# STM32H7RSxx register map
File version: 0.2
CPU: CM7 r0p1, little endian, MPU, FPU, 4 interrupt priority bits
Registers are 32-bit, read-write, reset 0x0 unless marked. A register's access mark holds for its fields unless they carry their own. Offsets are from the block's base; [hi:lo] are bit positions; {n}, {i} and the like mark numbered series; 'fields as' and 'values as' point back to an identical list.

## TIM9 — General-purpose timers
Base 0x42004C00
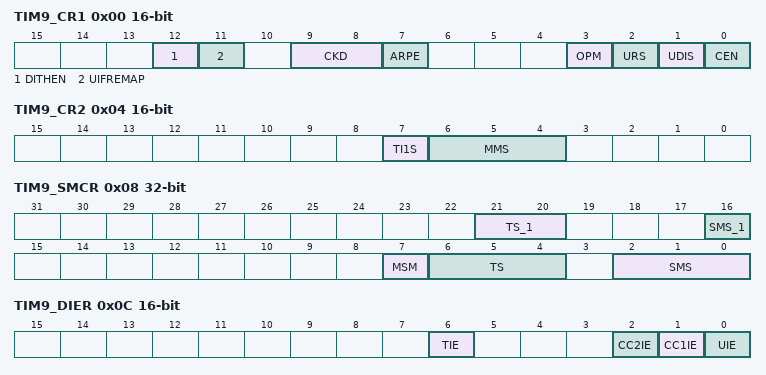
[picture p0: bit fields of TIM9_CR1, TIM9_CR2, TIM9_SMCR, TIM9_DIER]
0x00 TIM9_CR1 16-bit — TIM9 control register 1
  [12] DITHEN — Dithering enable Note: The DITHEN bit can only be modified when CEN bit is reset.
    0=Dithering disabled; 1=Dithering enabled
  [11] UIFREMAP — UIF status bit remapping
    0=No remapping. UIF status bit is not copied to TIMx_CNT register bit 31.; 1=Remapping enabled. UIF status bit is copied to TIMx_CNT register bit 31.
  [9:8] CKD — Clock division This bit-field indicates the division ratio between the timer clock (tim_ker_ck) frequency and sampling clock used by the digital filters (tim_tix),
    0=t<sub>DTS</sub> = t<sub>tim_ker_ck</sub>; 1=t<sub>DTS</sub> = 2 � t<sub>tim_ker_ck</sub>; 2=t<sub>DTS</sub> = 4 � t<sub>tim_ker_ck</sub>
  [7] ARPE — Auto-reload preload enable
    0=TIMx_ARR register is not buffered; 1=TIMx_ARR register is buffered
  [3] OPM — One-pulse mode
    0=Counter is not stopped on the update event; 1=Counter stops counting on the next update event (clearing the CEN bit)
  [2] URS — Update request source This bit is set and cleared by software to select the UEV event sources. Counter overflow Setting the UG bit Update generation through the slave mode controller
    0=Any of the following events generates an update interrupt if enabled. These events can be:; 1=Only counter overflow generates an update interrupt if enabled
  [1] UDIS — Update disable This bit is set and cleared by software to enable/disable update event (UEV) generation. Counter overflow Setting the UG bit Buffered registers are then loaded with their preload values.
    0=UEV enabled. An UEV is generated by one of the following events:; 1=UEV disabled. No UEV is generated, shadow registers keep their value (ARR, PSC, CCRx). The counter and the prescaler are reinitialized if the UG bit is set.
  [0] CEN — Counter enable CEN is cleared automatically in one-pulse mode, when an update event occurs. Note: External clock and gated mode can work only if the CEN bit has been previously set by software. However trigger mode can set the CEN bit automatically by hardware.
    0=Counter disabled; 1=Counter enabled
0x04 TIM9_CR2 16-bit — TIM12 control register 2
  [7] TI1S — tim_ti1 selection
    0=The tim_ti1_in[15:0] multiplexer output is connected to tim_ti1 input; 1=The tim_ti1_in[15:0] and tim_ti2_in[15:0] multiplexers output are connected to the tim_ti1 input (XOR combination)
  [6:4] MMS — Master mode selection These bits allow to select the information to be sent in master mode to slave timers for synchronization (tim_trgo). The combination is as follows:
    0=Reset - the UG bit from the TIMx_EGR register is used as trigger output (tim_trgo). If the reset is generated by the trigger input (slave mode controller configured in reset mode) then the signal on tim_trgo is delayed compared to the actual reset.; 1=Enable - the Counter Enable signal CNT_EN is used as trigger output (tim_trgo). It is useful to start several timers at the same time or to control a window in which a slave timer is enable. The Counter Enable signal is generated by a logic AND between CEN control bit and the trigger input when configured in gated mode. When the Counter Enable signal is controlled by the trigger input, there is a delay on tim_trgo, except if the master/slave mode is selected (see the MSM bit description in TIMx_SMCR register).; 2=Update - The update event is selected as trigger output (tim_trgo). For instance a master timer can then be used as a prescaler for a slave timer.; 3=Compare Pulse - The trigger output send a positive pulse when the CC1IF flag is to be set (even if it was already high), as soon as a capture or a compare match occurred (tim_trgo); 4=Compare - tim_oc1refc signal is used as trigger output (tim_trgo); 5=Compare - tim_oc2refc signal is used as trigger output (tim_trgo)
0x08 TIM9_SMCR — TIM9 slave mode control register
  [21:20] TS_1 — TS[4:3]
  [16] SMS_1 — SMS[3]
  [7] MSM — Master/Slave mode
    0=No action; 1=The effect of an event on the trigger input (tim_trgi) is delayed to allow a perfect synchronization between the current timer and its slaves (through tim_trgo). It is useful in order to synchronize several timers on a single external event.
  [6:4] TS — TS[0]: Trigger selection This TS[4:0] bitfield selects the trigger input to be used to synchronize the counter. Others: Reserved See Table 658: TIMx internal trigger connection for more details on the meaning of tim_itrx for each timer. Note: These bits must be changed only when they are not used (for example when SMS=’000’) to avoid wrong edge detections at the transition.
    {v}=Internal Trigger {v} (tim_itr{v}) (v=0..3); 4=tim_ti1 Edge Detector (tim_ti1f_ed); 5=Filtered Timer Input 1 (tim_ti1fp1); 6=Filtered Timer Input 2 (tim_ti2fp2); {v}=Internal Trigger {v-4} (tim_itr{v-4}) (v=8..14); {v}=Internal Trigger 10 (tim_itr{v-4}) (v=15..19)
  [2:0] SMS — SMS[0]: Slave mode selection When external signals are selected the active edge of the trigger signal (tim_trgi) is linked to the polarity selected on the external input (see Input Control register and Control Register description. Other codes: reserved. Note: The gated mode (including gated + reset mode) must not be used if tim_ti1f_ed is selected as the trigger input (TS=’00100’). Indeed, tim_ti1f_ed outputs 1 pulse for each transition on tim_ti1f, whereas the gated mode checks the level of the trigger signal. Note: The clock of the slave peripherals (timer, ADC,...) receiving the tim_trgo signals must be enabled prior to receive events from the master timer, and must not be changed on-the-fly while triggers are received from the master timer.
    0=Slave mode disabled - if CEN = ‘1’ then the prescaler is clocked directly by the internal clock; 4=Reset Mode - Rising edge of the selected trigger input (tim_trgi) reinitializes the counter and generates an update of the registers; 5=Gated Mode - The counter clock is enabled when the trigger input (tim_trgi) is high. The counter stops (but is not reset) as soon as the trigger becomes low. Both start and stop of the counter are controlled.; 6=Trigger Mode - The counter starts at a rising edge of the trigger tim_trgi (but it is not reset). Only the start of the counter is controlled.; 7=External Clock Mode 1 - Rising edges of the selected trigger (tim_trgi) clock the counter; 8=Combined reset + trigger mode - Rising edge of the selected trigger input (tim_trgi) reinitializes the counter, generates an update of the registers and starts the counter; 9=Combined gated + reset mode - The counter clock is enabled when the trigger input (tim_trgi) is high. The counter stops and is reset) as soon as the trigger becomes low. Both start and stop of the counter are controlled.
0x0C TIM9_DIER 16-bit — TIM9 Interrupt enable register
  [6] TIE — Trigger interrupt enable
    0=Trigger interrupt disabled; 1=Trigger interrupt enabled
  [2] CC2IE — Capture/Compare 2 interrupt enable
    0=CC2 interrupt disabled; 1=CC2 interrupt enabled
  [1] CC1IE — Capture/Compare 1 interrupt enable
    0=CC1 interrupt disabled; 1=CC1 interrupt enabled
  [0] UIE — Update interrupt enable
    0=Update interrupt disabled; 1=Update interrupt enabled
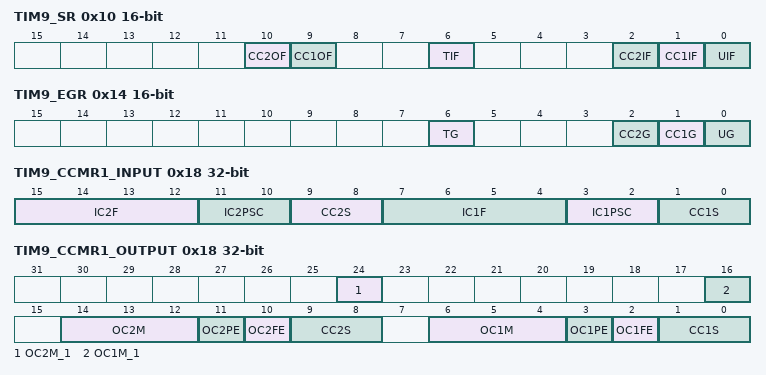
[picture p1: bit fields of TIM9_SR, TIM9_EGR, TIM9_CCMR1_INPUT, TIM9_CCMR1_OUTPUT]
0x10 TIM9_SR 16-bit — TIM9 status register
  [10] CC2OF — Capture/compare 2 overcapture flag refer to CC1OF description
  [9] CC1OF — Capture/Compare 1 overcapture flag This flag is set by hardware only when the corresponding channel is configured in input capture mode. It is cleared by software by writing it to ‘0’.
    0=No overcapture has been detected; 1=The counter value has been captured in TIMx_CCR1 register while CC1IF flag was already set
  [6] TIF — Trigger interrupt flag This flag is set by hardware on the TRG trigger event (active edge detected on tim_trgi input when the slave mode controller is enabled in all modes but gated mode. It is set when the counter starts or stops when gated mode is selected. It is cleared by software.
    0=No trigger event occurred; 1=Trigger interrupt pending
  [2] CC2IF — Capture/Compare 2 interrupt flag refer to CC1IF description
  [1] CC1IF — Capture/compare 1 interrupt flag This flag is set by hardware. It is cleared by software (input capture or output compare mode) or by reading the TIMx_CCR1 register (input capture mode only). If channel CC1 is configured as output: this flag is set when he content of the counter TIMx_CNT matches the content of the TIMx_CCR1 register. When the content of TIMx_CCR1 is greater than the content of TIMx_ARR, the CC1IF bit goes high on the counter overflow (in up-counting and up/down-counting modes) or underflow (in down-counting mode). There are 3 possible options for flag setting in center-aligned mode, refer to the CMS bits in the TIMx_CR1 register for the full description. If channel CC1 is configured as input: this bit is set when counter value has been captured in TIMx_CCR1 register (an edge has been detected on tim_ic1, as per the edge sensitivity defined with the CC1P and CC1NP bits setting, in TIMx_CCER).
    0=No compare match / No input capture occurred; 1=A compare match or an input capture occurred
  [0] UIF — Update interrupt flag This bit is set by hardware on an update event. It is cleared by software. At overflow and if UDIS=’0’ in the TIMx_CR1 register. When CNT is reinitialized by software using the UG bit in TIMx_EGR register, if URS=’0’ and UDIS=’0’ in the TIMx_CR1 register. When CNT is reinitialized by a trigger event (refer toSection 67.7.3: TIMx slave mode control register (TIMx_SMCR)(x = 9, 12) ), if URS=’0’ and UDIS=’0’ in the TIMx_CR1 register.
    0=No update occurred; 1=Update interrupt pending. This bit is set by hardware when the registers are updated:
0x14 TIM9_EGR 16-bit wo — TIM9 event generation register
  [6] TG — Trigger generation This bit is set by software in order to generate an event, it is automatically cleared by hardware.
    0=No action; 1=The TIF flag is set in the TIMx_SR register. Related interrupt can occur if enabled
  [2] CC2G — Capture/compare 2 generation refer to CC1G description
  [1] CC1G — Capture/compare 1 generation This bit is set by software to generate an event, it is automatically cleared by hardware. If channel CC1 is configured as output: the CC1IF flag is set, the corresponding interrupt is sent if enabled. If channel CC1 is configured as input: The current counter value is captured in the TIMx_CCR1 register. The CC1IF flag is set, the corresponding interrupt is sent if enabled. The CC1OF flag is set if the CC1IF flag was already high.
    0=No action; 1=A capture/compare event is generated on channel 1:
  [0] UG — Update generation This bit can be set by software, it is automatically cleared by hardware.
    0=No action; 1=Re-initializes the counter and generates an update of the registers. The prescaler counter is also cleared and the prescaler ratio is not affected. The counter is cleared.
0x18 TIM9_CCMR1_INPUT — TIM9 capture/compare mode register 1
  [15:12] IC2F — Input capture 2 filter
  [11:10] IC2PSC — Input capture 2 prescaler
  [9:8] CC2S — Capture/compare 2 selection This bitfield defines the direction of the channel (input/output) as well as the used input. Note: The CC2S bits are writable only when the channel is OFF (CC2E = 0 in TIMx_CCER).
    0=CC2 channel is configured as output; 1=CC2 channel is configured as input, IC2 is mapped on tim_ti2; 2=CC2 channel is configured as input, IC2 is mapped on tim_ti1; 3=CC2 channel is configured as input, IC2 is mapped on tim_trc. This mode works only if an internal trigger input is selected through the TS bit (TIMx_SMCR register)
  [7:4] IC1F — Input capture 1 filter This bitfield defines the frequency used to sample the tim_ti1 input and the length of the digital filter applied to tim_ti1. The digital filter is made of an event counter in which N consecutive events are needed to validate a transition on the output:
    0=No filter, sampling is done at f<sub>DTS</sub>; 1=f<sub>SAMPLING</sub>=f<sub>tim_ker_ck</sub>, N=2; 2=f<sub>SAMPLING</sub>=f<sub>tim_ker_ck</sub>, N=4; 3=f<sub>SAMPLING</sub>=f<sub>tim_ker_ck</sub>, N=8; 4=f<sub>SAMPLING</sub>=f<sub>DTS</sub>/2, N=6; 5=f<sub>SAMPLING</sub>=f<sub>DTS</sub>/2, N=8; 6=f<sub>SAMPLING</sub>=f<sub>DTS</sub>/4, N=6; 7=f<sub>SAMPLING</sub>=f<sub>DTS</sub>/4, N=8; 8=f<sub>SAMPLING</sub>=f<sub>DTS</sub>/8, N=6; 9=f<sub>SAMPLING</sub>=f<sub>DTS</sub>/8, N=8; 10=f<sub>SAMPLING</sub>=f<sub>DTS</sub>/16, N=5; 11=f<sub>SAMPLING</sub>=f<sub>DTS</sub>/16, N=6; 12=f<sub>SAMPLING</sub>=f<sub>DTS</sub>/16, N=8; 13=f<sub>SAMPLING</sub>=f<sub>DTS</sub>/32, N=5; 14=f<sub>SAMPLING</sub>=f<sub>DTS</sub>/32, N=6; 15=f<sub>SAMPLING</sub>=f<sub>DTS</sub>/32, N=8
  [3:2] IC1PSC — Input capture 1 prescaler This bitfield defines the ratio of the prescaler acting on the CC1 input (tim_ic1). The prescaler is reset as soon as CC1E=’0’ (TIMx_CCER register).
    0=no prescaler, capture is done each time an edge is detected on the capture input; 1=capture is done once every 2 events; 2=capture is done once every 4 events; 3=capture is done once every 8 events
  [1:0] CC1S — Capture/Compare 1 selection This bitfield defines the direction of the channel (input/output) as well as the used input. Note: The CC1S bits are writable only when the channel is OFF (CC1E = 0 in TIMx_CCER).
    0=CC1 channel is configured as output; 1=CC1 channel is configured as input, tim_ic1 is mapped on tim_ti1; 2=CC1 channel is configured as input, tim_ic1 is mapped on tim_ti2; 3=CC1 channel is configured as input, tim_ic1 is mapped on tim_trc. This mode is working only if an internal trigger input is selected through TS bit (TIMx_SMCR register)
0x18 TIM9_CCMR1_OUTPUT (alternate view of TIM9_CCMR1_INPUT) — TIM9 capture/compare mode register 1
  [24] OC2M_1 — OC2M[3]
  [16] OC1M_1 — OC1M[3]
  [14:12] OC2M — OC2M[2:0]: Output compare 2 mode Refer to OC1M[3:0] for bit description.
  [11] OC2PE — Output compare 2 preload enable
  [10] OC2FE — Output compare 2 fast enable
  [9:8] CC2S — Capture/Compare 2 selection This bitfield defines the direction of the channel (input/output) as well as the used input. Note: The CC2S bits are writable only when the channel is OFF (CC2E = 0 in TIMx_CCER).
    0=CC2 channel is configured as output; 1=CC2 channel is configured as input, IC2 is mapped on tim_ti2; 2=CC2 channel is configured as input, IC2 is mapped on tim_ti1; 3=CC2 channel is configured as input, IC2 is mapped on tim_trc. This mode works only if an internal trigger input is selected through the TS bit (TIMx_SMCR register
  [6:4] OC1M — OC1M[2:0]: Output compare 1 mode (refer to bit 16 for OC1M[3]) These bits define the behavior of the output reference signal tim_oc1ref from which tim_oc1 is derived. tim_oc1ref is active high whereas the active level of tim_oc1 depends on the CC1P. Note: In PWM mode 1 or 2, the OCREF level changes only when the result of the comparison changes or when the output compare mode switches from “frozen” mode to “PWM” mode.
    0=Frozen - The comparison between the output compare register TIMx_CCR1 and the counter TIMx_CNT has no effect on the outputs.(this mode is used to generate a timing base); 1=Set channel 1 to active level on match. The tim_oc1ref signal is forced high when the TIMx_CNT counter matches the capture/compare register 1 (TIMx_CCR1).; 2=Set channel 1 to inactive level on match. The tim_oc1ref signal is forced low when the TIMx_CNT counter matches the capture/compare register 1 (TIMx_CCR1).; 3=Toggle - tim_oc1ref toggles when TIMx_CNT=TIMx_CCR1; 4=Force inactive level - tim_oc1ref is forced low; 5=Force active level - tim_oc1ref is forced high; 6=PWM mode 1 - channel 1 is active as long as TIMx_CNT<TIMx_CCR1 else it is inactive; 7=PWM mode 2 - channel 1 is inactive as long as TIMx_CNT<TIMx_CCR1 else it is active; 8=Retrigerrable OPM mode 1 - The channel is active until a trigger event is detected (on tim_trgi signal). Then, a comparison is performed as in PWM mode 1 and the channels becomes active again at the next update.; 9=Retrigerrable OPM mode 2 - The channel is inactive until a trigger event is detected (on tim_trgi signal). Then, a comparison is performed as in PWM mode 2 and the channels becomes inactive again at the next update.; 12=Combined PWM mode 1 - tim_oc1ref has the same behavior as in PWM mode 1. tim_oc1refc is the logical OR between tim_oc1ref and tim_oc2ref.; 13=Combined PWM mode 2 - tim_oc1ref has the same behavior as in PWM mode 2. tim_oc1refc is the logical AND between tim_oc1ref and tim_oc2ref.
  [3] OC1PE — Output compare 1 preload enable
    0=Preload register on TIMx_CCR1 disabled. TIMx_CCR1 can be written at anytime, the new value is taken into account immediately; 1=Preload register on TIMx_CCR1 enabled. Read/Write operations access the preload register. TIMx_CCR1 preload value is loaded into the active register at each update event
  [2] OC1FE — Output compare 1 fast enable This bit is used to accelerate the effect of an event on the trigger in input on the CC output.
    0=CC1 behaves normally depending on the counter and CCR1 values even when the trigger is ON. The minimum delay to activate the CC1 output when an edge occurs on the trigger input is 5 clock cycles; 1=An active edge on the trigger input acts like a compare match on the CC1 output. Then, OC is set to the compare level independently of the result of the comparison. Delay to sample the trigger input and to activate CC1 output is reduced to 3 clock cycles. OC1FE acts only if the channel is configured in PWM1 or PWM2 mode.
  [1:0] CC1S — Capture/Compare 1 selection This bitfield defines the direction of the channel (input/output) as well as the used input. Note: The CC1S bits are writable only when the channel is OFF (CC1E = 0 in TIMx_CCER).
    0=CC1 channel is configured as output; 1=CC1 channel is configured as input, tim_ic1 is mapped on tim_ti1; 2=CC1 channel is configured as input, tim_ic1 is mapped on tim_ti2; 3=CC1 channel is configured as input, tim_ic1 is mapped on tim_trc. This mode works only if an internal trigger input is selected through the TS bit (TIMx_SMCR register)
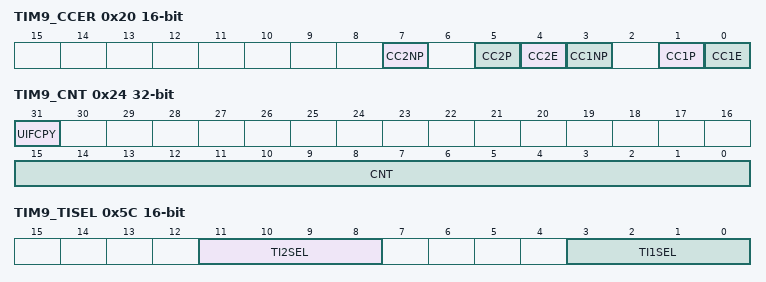
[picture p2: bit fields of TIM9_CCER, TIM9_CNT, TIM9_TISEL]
0x20 TIM9_CCER 16-bit — TIM9 capture/compare enable register
  [7] CC2NP — Capture/Compare 2 output Polarity Refer to CC1NP description
  [5] CC2P — Capture/Compare 2 output Polarity Refer to CC1P description
  [4] CC2E — Capture/Compare 2 output enable Refer to CC1E description
  [3] CC1NP — Capture/Compare 1 complementary output Polarity CC1 channel configured as output: CC1NP must be kept cleared CC1 channel configured as input: CC1NP is used in conjunction with CC1P to define tim_ti1fp1/tim_ti2fp1 polarity (refer to CC1P description).
  [1] CC1P — Capture/Compare 1 output Polarity. When CC1 channel is configured as input, both CC1NP/CC1P bits select the active polarity of tim_ti1fp1 and tim_ti2fp1 for trigger or capture operations. CC1NP=0, CC1P=0: non-inverted/rising edge. The circuit is sensitive to tim_tixfp1 rising edge (capture or trigger operations in reset, external clock or trigger mode), tim_tixfp1 is not inverted (trigger operation in gated mode or encoder mode). CC1NP=0, CC1P=1: inverted/falling edge. The circuit is sensitive to tim_tixfp1 falling edge (capture or trigger operations in reset, external clock or trigger mode), tim_tixfp1 is inverted (trigger operation in gated mode or encoder mode). CC1NP=1, CC1P=1: non-inverted/both edges/ The circuit is sensitive to both tim_tixfp1 rising and falling edges (capture or trigger operations in reset, external clock or trigger mode), tim_tixfp1 is not inverted (trigger operation in gated mode). This configuration must not be used in encoder mode. CC1NP=1, CC1P=0: This configuration is reserved, it must not be used.
    0=tim_oc1 active high (output mode) / Edge sensitivity selection (input mode, see below); 1=tim_oc1 active low (output mode) / Edge sensitivity selection (input mode, see below)
  [0] CC1E — Capture/Compare 1 output enable.
    0=Capture mode disabled / tim_oc1 is not active; 1=Capture mode enabled / tim_oc1 signal is output on the corresponding output pin
0x24 TIM9_CNT — TIM9 counter
  [31] UIFCPY — UIF Copy This bit is a read-only copy of the UIF bit in the TIMx_ISR register.
  [15:0] CNT — Counter value Non-dithering mode (DITHEN = 0) The register holds the counter value. Dithering mode (DITHEN = 1) The register only holds the non-dithered part in CNT[15:0]. The fractional part is not available.
0x28 TIM9_PSC 16-bit — TIM9 prescaler
  [15:0] PSC — Prescaler value The counter clock frequency tim_cnt_ck is equal to f<sub>tim_psc_ck</sub> / (PSC[15:0] + 1). PSC contains the value to be loaded into the active prescaler register at each update event. (including when the counter is cleared through UG bit of TIMx_EGR register or through trigger controller when configured in “reset mode”).
0x2C TIM9_ARR reset 0xFFFF — TIM9 auto-reload register
  [19:0] ARR — Auto-reload value ARR is the value to be loaded in the actual auto-reload register. Refer to the Section 67.4.3: Time-base unit on page 3951 for more details about ARR update and behavior. The counter is blocked while the auto-reload value is null. Non-dithering mode (DITHEN = 0) The register holds the auto-reload value in ARR[15:0]. The ARR[19:16] bits are reset. Dithering mode (DITHEN = 1) The register holds the integer part in ARR[19:4]. The ARR[3:0] bitfield contains the dithered part.
0x34 TIM9_CCR1 — TIM9 capture/compare register 1
  [19:0] CCR1 — Capture/compare 1 value If channel CC1 is configured as output: CCR1 is the value to be loaded in the actual capture/compare 1 register (preload value). It is loaded permanently if the preload feature is not selected in the TIMx_CCMR1 register (bit OC1PE). Else the preload value is copied in the active capture/compare 1 register when an update event occurs. The active capture/compare register contains the value to be compared to the counter TIMx_CNT and signaled on tim_oc1 output. Non-dithering mode (DITHEN = 0) The register holds the compare value in CCR1[15:0]. The CCR1[19:16] bits are reset. Dithering mode (DITHEN = 1) The register holds the integer part in CCR1[19:4]. The CCR1[3:0] bitfield contains the dithered part. If channel CC1 is configured as input: CR1 is the counter value transferred by the last input capture 1 event (tim_ic1). The TIMx_CCR1 register is read-only and cannot be programmed. Non-dithering mode (DITHEN = 0) The register holds the capture value in CCR1[15:0]. The CCR1[19:16] bits are reset. Dithering mode (DITHEN = 1) The register holds the capture in CCR1[19:4]. The CCR1[3:0] bits are reset.
0x38 TIM9_CCR2 — TIM9 capture/compare register 2
  [19:0] CCR2 — Capture/compare 2 value If channel CC2 is configured as output: CCR2 is the value to be loaded in the actual capture/compare 2 register (preload value). It is loaded permanently if the preload feature is not selected in the TIMx_CCMR2 register (bit OC2PE). Else the preload value is copied in the active capture/compare 2 register when an update event occurs. The active capture/compare register contains the value to be compared to the counter TIMx_CNT and signalled on tim_oc2 output. Non-dithering mode (DITHEN = 0) The register holds the compare value in CCR2[15:0]. The CCR2[19:16] bits are reset. Dithering mode (DITHEN = 1) The register holds the integer part in CCR2[19:4]. The CCR2[3:0] bitfield contains the dithered part. If channel CC2 is configured as input: CCR2 is the counter value transferred by the last input capture 1 event (tim_ic2). The TIMx_CCR2 register is read-only and cannot be programmed. Non-dithering mode (DITHEN = 0) The register holds the capture value in CCR2[15:0]. The CCR2[19:16] bits are reset. Dithering mode (DITHEN = 1) The register holds the capture in CCR2[19:4]. The CCR2[3:0] bits are reset.
0x5C TIM9_TISEL 16-bit — TIM9 timer input selection register
  [11:8] TI2SEL — selects tim_ti2_in[15:0] input ... Refer to Table 657: Interconnect to the tim_ti2 input multiplexer for interconnects list.
    0=TIMx_CH2 input (tim_ti2_in0); 1=tim_ti2_in1; 4=tim_ti2_in15
  [3:0] TI1SEL — selects tim_ti1_in[15:0] input ... Refer to Table 656: Interconnect to the tim_ti1 input multiplexer for interconnects list.
    0=TIMx_CH1 input (tim_ti1_in0); 1=tim_ti1_in1; 15=tim_ti1_in15

## TIM12 — General-purpose timers
Base 0x40001800
Registers as TIM9 (with TIM9 read as TIM12); these are added or differ:
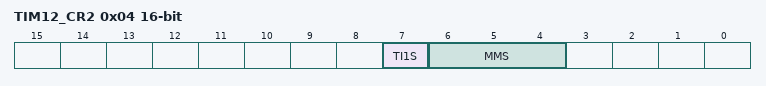
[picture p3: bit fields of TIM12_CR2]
0x04 TIM12_CR2 16-bit — TIM12 control register 2
  fields as TIM9.TIM9_CR2
